# GD32VW553x register map
Vendor: GigaDevice; File version: 1.0
CPU: OTHER r0p0, little endian, no MPU, no FPU, 4 interrupt priority bits
Registers are 32-bit, read-write, reset 0x0 unless marked. A register's access mark holds for its fields unless they carry their own. Offsets are from the block's base; [hi:lo] are bit positions; {n}, {i} and the like mark numbered series.

## ECLIC — Enhanced Core Local Interrupt Controller
Base 0xD2000000
0x00 CLICCFG 8-bit
  [4:1] NLBITS
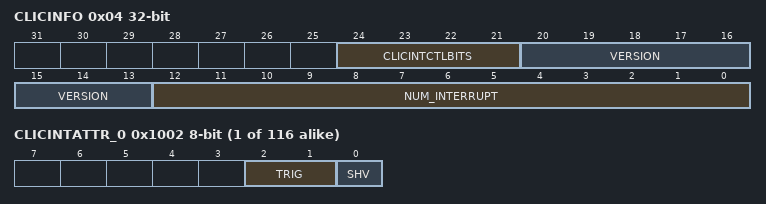
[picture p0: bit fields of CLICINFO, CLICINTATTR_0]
0x04 CLICINFO ro
  [24:21] CLICINTCTLBITS, [20:13] VERSION, [12:0] NUM_INTERRUPT
0x0B MTH 8-bit
{0x1000+4i} CLICINTIP_{i} 8-bit (i=0..115) — clicintip Register
  [0] IP
{0x1001+4i} CLICINTIE_{i} 8-bit (i=0..115) — clicintie Register
  [0] IE
{0x1002+4i} CLICINTATTR_{i} 8-bit (i=0..115) — clicintattr Register
  [2:1] TRIG, [0] SHV
{0x1003+4i} CLICINTCTL_{i} 8-bit (i=0..115) — clicintctl Register
  [7:0] LEVEL_PRIORITY

## EFUSE — Electronic fuse
Base 0x40022800
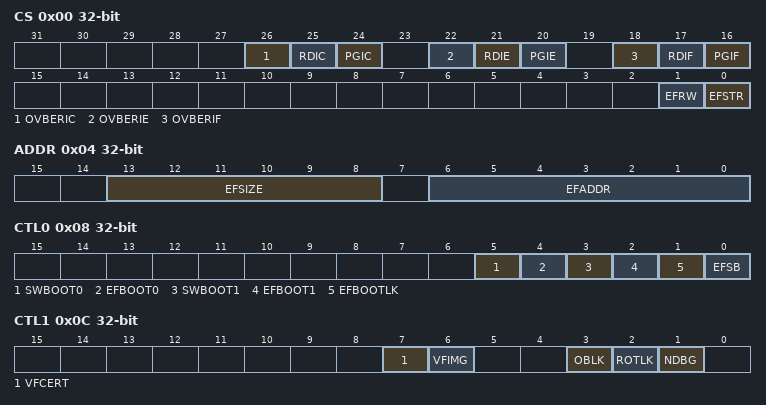
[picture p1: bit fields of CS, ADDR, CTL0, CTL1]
0x00 CS — Control and status register
  [26] OVBERIC — Clear bit for overstep boundary error interrupt flag
  [25] RDIC — Clear bit for read operation completed interrupt flag
  [24] PGIC — Clear bit for program operation completed interrupt flag
  [22] OVBERIE — Enable bit for overstep boundary error interrupt
  [21] RDIE — Enable bit for read operation completed interrupt
  [20] PGIE — Enable bit for program operation completed interrupt
  [18] OVBERIF ro — Overstep boundary error flag
  [17] RDIF ro — Read operation complete flag
  [16] PGIF ro — Program operation completed flag
  [1] EFRW — The selection of Efuse operation
  [0] EFSTR — Start Efuse operation
0x04 ADDR — Address register
  [13:8] EFSIZE — Read or write Efuse data size
  [6:0] EFADDR — Read or write Efuse data start address
0x08 CTL0 — Control register 0
  [5] SWBOOT0 — Efuse BOOT0 bit enable
  [4] EFBOOT0 — Efuse BOOT0
  [3] SWBOOT1 — Efuse BOOT1 bit enable
  [2] EFBOOT1 — Efuse BOOT1
  [1] EFBOOTLK — EFUSE_CTL0 register bits[5:2] lock bit
  [0] EFSB — Startup from secure boot
0x0C CTL1 — Control register 1
  [7] VFCERT — Verify firmware certificate
  [6] VFIMG — Verify firmware image
  [3] OBLK — Option bytes lock bit
  [2] ROTLK — EFUSE_ROTPK_KEY register lock bit
  [1] NDBG — Debugging permission setting
0x10 FPCTL — Flash protection control register
  [2:0] FP — Efuse flash protection value
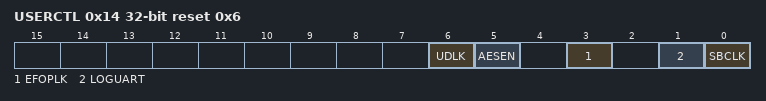
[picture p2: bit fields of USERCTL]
0x14 USERCTL reset 0x6 — User byte control register
  [6] UDLK — EFUSE_USER_DATA register lock bit
  [5] AESEN — Lock EFUSE_AES_KEY register and enable AES decrypt function
  [3] EFOPLK — EFUSE_FPCTL and EFUSE_USERCTL register lock bit
  [1] LOGUART — Secure Boot Log UART selection
  [0] SBCLK — Secure boot clock source selection
{0x18+4i} RES{i} (i=0..2) — EFUSE reserved register {i}
  [31:0] RES — Efuse reserved bytes
{0x24+4i} AESKEY{i} (i=0..3) — Firmware AES key register {i}
  [31:0] AESKEY — Efuse AES key value
{0x34+4i} ROTPKKEY{i} (i=0..7) — RoTPK key register {i}
  [31:0] RKEY — Efuse RoTPK or its HASH value
{0x54+4i} PUID{i} (i=0..3) — Product UID register {i}
  [31:0] UID ro — Efuse MCU UID value
{0x64+4i} HUKKEY{i} (i=0..3) — HUK key register {i}
  [31:0] HKEY ro — Efuse HUK key value
{0x74+4i} USER_DATA{i} (i=0..7) — User data register {i}
  [31:0] USERDATA — Efuse USER_DATA value
0x124 BOOTADDR — Boot address register
  [31:0] BOOTADDR ro — Boot from the address

## EXTI — External interrupt/event controller
Base 0x40013C00
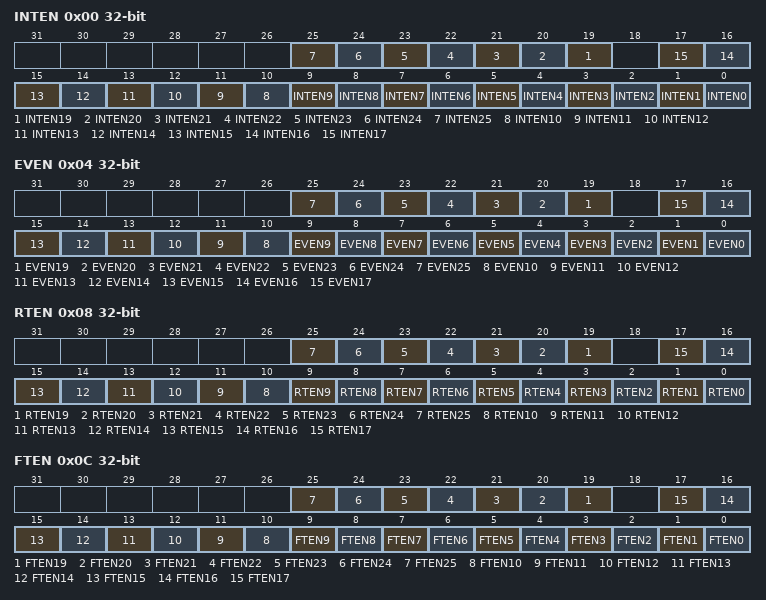
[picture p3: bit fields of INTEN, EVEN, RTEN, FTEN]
0x00 INTEN — Interrupt enable register (EXTI_INTEN)
  [n] INTEN{n} (n=19..25) — Enable Interrupt on line {n}
  [n] INTEN{n} (n=0..17) — Enable Interrupt on line {n}
0x04 EVEN — Event enable register (EXTI_EVEN)
  [n] EVEN{n} (n=19..25) — Enable Event on line {n}
  [n] EVEN{n} (n=0..17) — Enable Event on line {n}
0x08 RTEN — Rising Edge Trigger Enable register (EXTI_RTEN)
  [n] RTEN{n} (n=19..25) — Rising edge trigger enable of line {n}
  [n] RTEN{n} (n=0..17) — Rising edge trigger enable of line {n}
0x0C FTEN — Falling Egde Trigger Enable register (EXTI_FTEN)
  [n] FTEN{n} (n=19..25) — Falling edge trigger enable of line {n}
  [n] FTEN{n} (n=0..17) — Falling edge trigger enable of line {n}
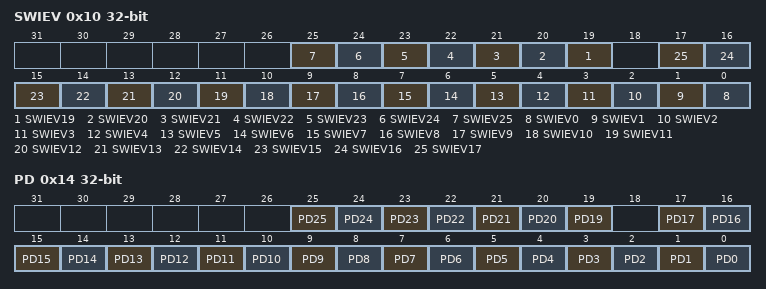
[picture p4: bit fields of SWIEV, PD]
0x10 SWIEV — Software interrupt event register (EXTI_SWIEV)
  [n] SWIEV{n} (n=19..25) — Interrupt/Event software trigger on line {n}
  [n] SWIEV{n} (n=0..17) — Interrupt/Event software trigger on line {n}
0x14 PD — Pending register (EXTI_PD)
  [n] PD{n} (n=19..25) — Interrupt pending status of line {n}
  [n] PD{n} (n=0..17) — Interrupt pending status of line {n}
